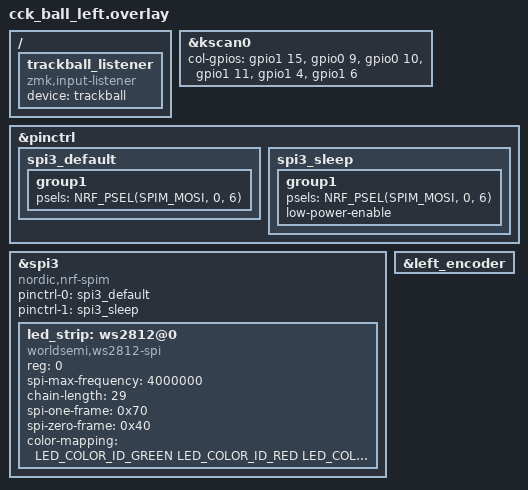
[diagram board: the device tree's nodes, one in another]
/*
 * Copyright (c) 2020 ZMK Contributors
 *
 * SPDX-License-Identifier: MIT
 */

#include <dt-bindings/zmk/matrix_transform.h>
#include <dt-bindings/led/led.h>
#include <dt-bindings/pinctrl/nrf-pinctrl.h>
#include "cck_ball.dtsi"

&kscan0 {
    col-gpios
        = <&gpio1 15 GPIO_ACTIVE_HIGH>
        , <&gpio0 9 GPIO_ACTIVE_HIGH>
        , <&gpio0 10 GPIO_ACTIVE_HIGH>
        , <&gpio1 11 GPIO_ACTIVE_HIGH>
        , <&gpio1 4 GPIO_ACTIVE_HIGH>
        , <&gpio1 6 GPIO_ACTIVE_HIGH>
        ;
};

// RGB bus configuration
&pinctrl {
    spi3_default: spi3_default {
        group1 {
            /* P0.10の競合を避けるためP0.06に変更 */
            psels = <NRF_PSEL(SPIM_MOSI, 0, 6)>;
        };
    };

    spi3_sleep: spi3_sleep {
        group1 {
            psels = <NRF_PSEL(SPIM_MOSI, 0, 6)>;
            low-power-enable;
        };
    };
};

&spi3 {
    compatible = "nordic,nrf-spim";
    status = "okay";

    pinctrl-0 = <&spi3_default>;
    pinctrl-1 = <&spi3_sleep>;
    pinctrl-names = "default", "sleep";

    led_strip: ws2812@0 {
        compatible = "worldsemi,ws2812-spi";

        /* SPI */
        reg = <0>;
        spi-max-frequency = <4000000>;

        /* WS2812 */
        chain-length = <29>;
        spi-one-frame = <0x70>;
        spi-zero-frame = <0x40>;
        color-mapping = <LED_COLOR_ID_GREEN
                         LED_COLOR_ID_RED
                         LED_COLOR_ID_BLUE>;
    };
};

// トラックボールの信号を左側で受信するための設定
/ {
    trackball_listener {
        compatible = "zmk,input-listener";
        device = <&trackball>;
    };
};

// enable left encoder
&left_encoder {
    status = "okay";
};
